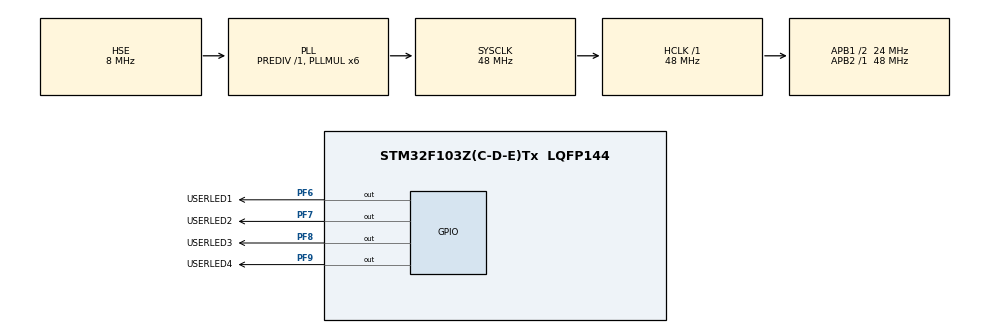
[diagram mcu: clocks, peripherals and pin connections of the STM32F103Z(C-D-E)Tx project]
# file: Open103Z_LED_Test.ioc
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Mcu.Family=STM32F1
Mcu.Name=STM32F103Z(C-D-E)Tx
Mcu.Package=LQFP144
NVIC.PriorityGroup=NVIC_PRIORITYGROUP_4
OSC_IN.Mode=HSE-External-Oscillator
OSC_IN.Signal=RCC_OSC_IN
OSC_OUT.Mode=HSE-External-Oscillator
OSC_OUT.Signal=RCC_OSC_OUT
PA13.Mode=Serial_Wire
PA13.Signal=SYS_JTMS-SWDIO
PA14.Mode=Serial_Wire
PA14.Signal=SYS_JTCK-SWCLK
PF6.GPIO_Label=USERLED1
PF6.Signal=GPIO_Output
PF7.GPIO_Label=USERLED2
PF7.Signal=GPIO_Output
PF8.GPIO_Label=USERLED3
PF8.Signal=GPIO_Output
PF9.GPIO_Label=USERLED4
PF9.Signal=GPIO_Output
ProjectManager.TargetToolchain=TrueSTUDIO
RCC.AHBFreq_Value=48000000
RCC.APB1CLKDivider=RCC_HCLK_DIV2
RCC.APB1Freq_Value=24000000
RCC.APB1TimFreq_Value=48000000
RCC.APB2Freq_Value=48000000
RCC.APB2TimFreq_Value=48000000
RCC.HCLKFreq_Value=48000000
RCC.HSIState=RCC_HSI_ON
RCC.PLLMUL=RCC_PLL_MUL6
RCC.PLLSourceVirtual=RCC_PLLSOURCE_HSE
RCC.SYSCLKFreq_VALUE=48000000
RCC.SYSCLKSource=RCC_SYSCLKSOURCE_PLLCLK
RCC.USBFreq_Value=48000000
board=Open103Z_LED_Test

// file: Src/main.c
#include "stm32f1xx_hal.h"

/* USER CODE BEGIN PV */
/* Private variables ---------------------------------------------------------*/

/* USER CODE END PV */

void SystemClock_Config(void);
static void MX_GPIO_Init(void);

/* USER CODE BEGIN PFP */
/* Private function prototypes -----------------------------------------------*/

/* USER CODE END PFP */

int main(void)
{
	int wait_ms;

  /* MCU Configuration----------------------------------------------------------*/

  /* Reset of all peripherals, Initializes the Flash interface and the Systick. */
  HAL_Init();

  /* Configure the system clock */
  SystemClock_Config();

  /* Initialize all configured peripherals */
  MX_GPIO_Init();

  /* Infinite loop */
  /* USER CODE BEGIN WHILE */
  wait_ms = 500;
  while (1)
  {
  /* USER CODE END WHILE */

  /* USER CODE BEGIN 3 */
	  HAL_GPIO_WritePin(GPIOF, USERLED1_Pin, GPIO_PIN_SET);

	  if (wait_ms) {
		  HAL_Delay(wait_ms);
		  HAL_GPIO_WritePin(GPIOF, USERLED1_Pin, GPIO_PIN_RESET);
		  HAL_Delay(wait_ms);
		  if (wait_ms > 300)
			  wait_ms -= 100;
		  else if (wait_ms > 200)
			  wait_ms -= 50;
		  else if (wait_ms > 100)
			  wait_ms -= 10;
		  else
			  wait_ms -= 2;
	  }
  }
  /* USER CODE END 3 */

}

/** System Clock Configuration
*/
void SystemClock_Config(void)
{

  RCC_OscInitTypeDef RCC_OscInitStruct;
  RCC_ClkInitTypeDef RCC_ClkInitStruct;

  RCC_OscInitStruct.OscillatorType = RCC_OSCILLATORTYPE_HSE;
  RCC_OscInitStruct.HSEState = RCC_HSE_ON;
  RCC_OscInitStruct.HSEPredivValue = RCC_HSE_PREDIV_DIV1;
  RCC_OscInitStruct.PLL.PLLState = RCC_PLL_ON;
  RCC_OscInitStruct.PLL.PLLSource = RCC_PLLSOURCE_HSE;
  RCC_OscInitStruct.PLL.PLLMUL = RCC_PLL_MUL6;
  HAL_RCC_OscConfig(&RCC_OscInitStruct);

  RCC_ClkInitStruct.ClockType = RCC_CLOCKTYPE_SYSCLK|RCC_CLOCKTYPE_PCLK1;
  RCC_ClkInitStruct.SYSCLKSource = RCC_SYSCLKSOURCE_PLLCLK;
  RCC_ClkInitStruct.AHBCLKDivider = RCC_SYSCLK_DIV1;
  RCC_ClkInitStruct.APB1CLKDivider = RCC_HCLK_DIV2;
  RCC_ClkInitStruct.APB2CLKDivider = RCC_HCLK_DIV1;
  HAL_RCC_ClockConfig(&RCC_ClkInitStruct, FLASH_LATENCY_1);

  HAL_SYSTICK_Config(HAL_RCC_GetHCLKFreq()/1000);

  HAL_SYSTICK_CLKSourceConfig(SYSTICK_CLKSOURCE_HCLK);

  /* SysTick_IRQn interrupt configuration */
  HAL_NVIC_SetPriority(SysTick_IRQn, 0, 0);
}

/** Configure pins as
        * Analog
        * Input
        * Output
        * EVENT_OUT
        * EXTI
*/
void MX_GPIO_Init(void)
{

  GPIO_InitTypeDef GPIO_InitStruct;

  /* GPIO Ports Clock Enable */
  __GPIOF_CLK_ENABLE();
  __GPIOA_CLK_ENABLE();

  /*Configure GPIO pins : USERLED1_Pin USERLED2_Pin USERLED3_Pin USERLED4_Pin */
  GPIO_InitStruct.Pin = USERLED1_Pin|USERLED2_Pin|USERLED3_Pin|USERLED4_Pin;
  GPIO_InitStruct.Mode = GPIO_MODE_OUTPUT_PP;
  GPIO_InitStruct.Speed = GPIO_SPEED_LOW;
  HAL_GPIO_Init(GPIOF, &GPIO_InitStruct);

}

/************************ (C) COPYRIGHT STMicroelectronics *****END OF FILE****/
